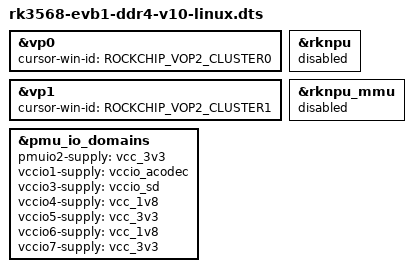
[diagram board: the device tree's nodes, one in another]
// SPDX-License-Identifier: (GPL-2.0+ OR MIT)
/*
 * Copyright (c) 2020 Rockchip Electronics Co., Ltd.
 *
 */

#include "rk3568-evb1-ddr4-v10.dtsi"
#include "rk3568-linux.dtsi"
#include <dt-bindings/display/rockchip_vop.h>

&vp0 {
	cursor-win-id = <ROCKCHIP_VOP2_CLUSTER0>;
};

&vp1 {
	cursor-win-id = <ROCKCHIP_VOP2_CLUSTER1>;
};

&pmu_io_domains {
	status = "okay";
	pmuio2-supply = <&vcc_3v3>;
	vccio1-supply = <&vccio_acodec>;
	vccio3-supply = <&vccio_sd>;
	vccio4-supply = <&vcc_1v8>;
	vccio5-supply = <&vcc_3v3>;
	vccio6-supply = <&vcc_1v8>;
	vccio7-supply = <&vcc_3v3>;
};

&rknpu {
	status = "disabled";
};

&rknpu_mmu {
	status = "disabled";
};
